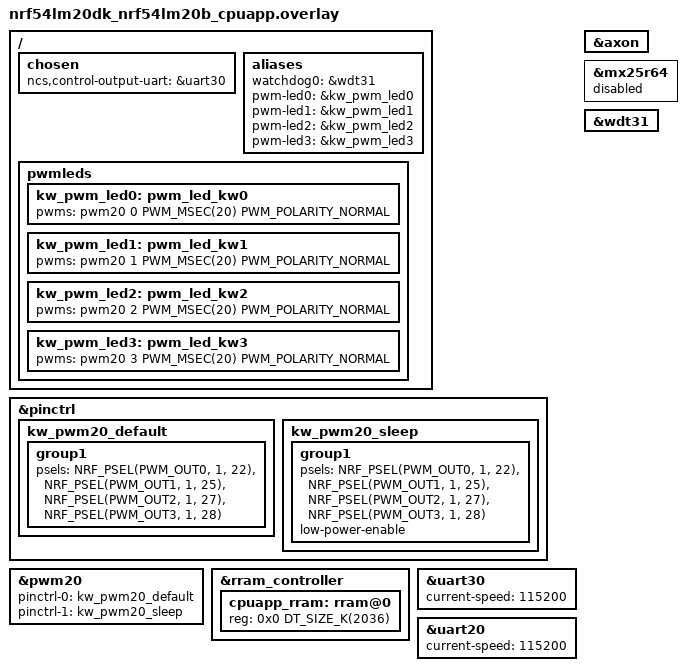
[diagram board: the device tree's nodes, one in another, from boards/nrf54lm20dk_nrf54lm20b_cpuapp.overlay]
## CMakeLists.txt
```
#
# Copyright (c) 2026 Nordic Semiconductor ASA
#
# SPDX-License-Identifier: LicenseRef-Nordic-5-Clause
#

cmake_minimum_required(VERSION 3.20.0)

find_package(Zephyr REQUIRED HINTS $ENV{ZEPHYR_BASE})
project(matter_switch)

# Enable GNU STD support.
include(${ZEPHYR_CONNECTEDHOMEIP_MODULE_DIR}/config/nrfconnect/app/enable-gnu-std.cmake)

# NORDIC SDK APP START

# Include all source files that are located in the Matter common directory.
include(${ZEPHYR_NRF_MODULE_DIR}/samples/matter/common/cmake/source_common.cmake)

# Include Data Model utils
include(${ZEPHYR_NRF_MODULE_DIR}/samples/matter/common/cmake/data_model.cmake)

include(${ZEPHYR_NRF_MODULE_DIR}/samples/matter/common/cmake/zap_helpers.cmake)
ncs_get_zap_parent_dir(ZAP_PARENT_DIR)

include(${ZEPHYR_NCS_MATTER_EDGE_AI_MODULE_DIR}/samples/common/matter_edge_ai_common.cmake)

target_include_directories(app PRIVATE
  src
  src/models/kws/nrf_edgeai_generated
  src/models/wakeword/nrf_edgeai_generated
  src/edgeAI
  ${ZAP_PARENT_DIR}
)

target_compile_options(app PRIVATE -Wno-deprecated-declarations)

target_sources(app PRIVATE
  src/main.cpp
  src/app_task.cpp
  src/nrf_edgeai_ww_kw_impl.cpp
  src/keyword_impl.c
  src/wakeword_impl.c
  src/models/wakeword/nrf_edgeai_generated/nrf_edgeai_user_model.c
  src/models/kws/nrf_edgeai_generated/nrf_edgeai_user_model.c
  src/generic_switch.cpp
)

ncs_configure_data_model()
```

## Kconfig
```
#
# Copyright (c) 2026 Nordic Semiconductor ASA
#
# SPDX-License-Identifier: LicenseRef-Nordic-5-Clause
#

# Sample configuration used for Thread networking
if OPENTHREAD

choice OPENTHREAD_NORDIC_LIBRARY_CONFIGURATION
	default OPENTHREAD_NORDIC_LIBRARY_MTD
endchoice

choice OPENTHREAD_DEVICE_TYPE
	default OPENTHREAD_MTD
endchoice

config CHIP_ENABLE_ICD_SUPPORT
	default y

# Reduce Thread TX output power to 0 dBm for SED device
config OPENTHREAD_DEFAULT_TX_POWER
	default 0

endif # OPENTHREAD

source "$(ZEPHYR_CONNECTEDHOMEIP_MODULE_DIR)/config/nrfconnect/chip-module/Kconfig.features"
source "$(ZEPHYR_CONNECTEDHOMEIP_MODULE_DIR)/config/nrfconnect/chip-module/Kconfig.defaults"
source "$(ZEPHYR_NRF_MODULE_DIR)/samples/matter/common/src/Kconfig"
source "Kconfig.zephyr"
```

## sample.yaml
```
sample:
  description: Matter Generic Switch application
  name: Matter Generic Switch

common:
  sysbuild: true
  build_only: true
  tags:
    - ci_build
    - sysbuild

tests:
  sample.matter.generic_switch.debug.dmic_adafruit:
    extra_args: 
      - EXTRA_DTC_OVERLAY_FILE=boards/dmic_adafruit.dtsi
    platform_allow:
      - nrf54lm20dk/nrf54lm20b/cpuapp
    integration_platforms:
      - nrf54lm20dk/nrf54lm20b/cpuapp
  sample.matter.generic_switch.debug.dmic_low_power:
    extra_args:
      - EXTRA_DTC_OVERLAY_FILE=boards/dmic_low_power.dtsi
    platform_allow:
      - nrf54lm20dk/nrf54lm20b/cpuapp
    integration_platforms:
      - nrf54lm20dk/nrf54lm20b/cpuapp
  sample.matter.generic_switch.debug.dmic_adafruit.release:
    extra_args:
      - EXTRA_DTC_OVERLAY_FILE=boards/dmic_adafruit.dtsi
      - FILE_SUFFIX=release
    platform_allow:
      - nrf54lm20dk/nrf54lm20b/cpuapp
    integration_platforms:
      - nrf54lm20dk/nrf54lm20b/cpuapp
  sample.matter.generic_switch.debug.dmic_low_power.release:
    extra_args:
      - EXTRA_DTC_OVERLAY_FILE=boards/dmic_low_power.dtsi
      - FILE_SUFFIX=release
    platform_allow:
      - nrf54lm20dk/nrf54lm20b/cpuapp
    integration_platforms:
      - nrf54lm20dk/nrf54lm20b/cpuapp
```

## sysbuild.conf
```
#
# Copyright (c) 2026 Nordic Semiconductor ASA
#
# SPDX-License-Identifier: LicenseRef-Nordic-5-Clause
#

SB_CONFIG_MATTER=y
SB_CONFIG_MATTER_FACTORY_DATA_GENERATE=y

SB_CONFIG_PARTITION_MANAGER=n

# Enable the DFU image compression.
SB_CONFIG_BOOTLOADER_MCUBOOT=y
SB_CONFIG_DFU_MULTI_IMAGE_PACKAGE_BUILD=y
SB_CONFIG_DFU_MULTI_IMAGE_PACKAGE_APP=y
SB_CONFIG_MCUBOOT_MODE_OVERWRITE_ONLY=y
SB_CONFIG_MCUBOOT_COMPRESSED_IMAGE_SUPPORT=y
```

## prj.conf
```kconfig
#
# Copyright (c) 2026 Nordic Semiconductor
#
# SPDX-License-Identifier: LicenseRef-Nordic-5-Clause
#

# Enable CHIP
CONFIG_CHIP=y
CONFIG_CHIP_PROJECT_CONFIG="src/chip_project_config.h"
CONFIG_CHIP_DEVICE_PRODUCT_NAME="Matter AI Switch"
CONFIG_NCS_SAMPLE_MATTER_ZAP_FILE_PATH="${APPLICATION_CONFIG_DIR}/src/generic_switch_zap/generic_switch.zap"

# 32772 == 0x8004 (example matter_switch-app)
CONFIG_CHIP_DEVICE_PRODUCT_ID=32772
CONFIG_STD_CPP17=y

# Enable Matter extended announcement and increase duration to 1 hour.
CONFIG_CHIP_BLE_EXT_ADVERTISING=y
CONFIG_CHIP_BLE_ADVERTISING_DURATION=60

# Add support for LEDs and buttons on Nordic development kits
CONFIG_DK_LIBRARY=y

# Bluetooth Low Energy configuration
CONFIG_BT_DEVICE_NAME="MatterAISwitch"

# Enable Matter pairing automatically on application start.
CONFIG_CHIP_ENABLE_PAIRING_AUTOSTART=y

# Suspend devices when the CPU goes into sleep
CONFIG_PM_DEVICE=y

# Other settings
CONFIG_THREAD_NAME=y
CONFIG_MPU_STACK_GUARD=y

CONFIG_SYSTEM_WORKQUEUE_STACK_SIZE=4096

# Memory: k_malloc pool + Matter chip heap are static (.bss) and sit before the Newlib arena
# (RAM from _end to top of SRAM). Edge AI uses malloc(); if that arena is too small, the first
# stdio/C++ lock init hits: "recursive lock allocation failed" in libc-hooks.c.
CONFIG_MAIN_STACK_SIZE=10240
CONFIG_COMMON_LIBC_MALLOC_ARENA_SIZE=-1
CONFIG_HEAP_MEM_POOL_SIZE=24576
CONFIG_CHIP_MALLOC_SYS_HEAP_SIZE=40960
CONFIG_CHIP_SYSTEM_PACKETBUFFER_POOL_SIZE=24
CONFIG_CHIP_TASK_STACK_SIZE=12288

CONFIG_MATTER_EDGEAI_TASK_THREAD_STACK_SIZE=8192
CONFIG_MATTER_EDGEAI_TASK_THREAD_PRIORITY=0

CONFIG_RESET_ON_FATAL_ERROR=n
CONFIG_CHIP_LIB_SHELL=y
CONFIG_NCS_SAMPLE_MATTER_TEST_SHELL=y

# Reduce application size
CONFIG_USE_SEGGER_RTT=n
CONFIG_MATTER_LOG_LEVEL_INF=y
CONFIG_CHIP_APP_LOG_LEVEL=3

# Enable Factory Data feature
CONFIG_CHIP_FACTORY_DATA=y
CONFIG_CHIP_FACTORY_DATA_BUILD=y

# Enable Matter Edge AI
CONFIG_FPU=y
CONFIG_MATTER_EDGEAI=y
CONFIG_MATTER_EDGEAI_DMIC=y
CONFIG_MATTER_EDGEAI_DIMMING=y

# Edge AI model configuration
CONFIG_NRF_AXON_INTERLAYER_BUFFER_SIZE=6656
CONFIG_NRF_AXON_PSUM_BUFFER_SIZE=0

# By default use Adafruit PDM module
```

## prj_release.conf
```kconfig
#
# Copyright (c) 2026 Nordic Semiconductor ASA
#
# SPDX-License-Identifier: LicenseRef-Nordic-5-Clause
#

# This sample uses Kconfig.defaults to set options common for all
# samples. This file should contain only options specific for this sample
# or overrides of default values.

# Enable CHIP
CONFIG_CHIP=y
CONFIG_CHIP_PROJECT_CONFIG="src/chip_project_config.h"
CONFIG_CHIP_DEVICE_PRODUCT_NAME="Matter AI Switch"
CONFIG_NCS_SAMPLE_MATTER_ZAP_FILE_PATH="${APPLICATION_CONFIG_DIR}/src/generic_switch_zap/generic_switch.zap"

# 32772 == 0x8004 (example matter_switch-app)
CONFIG_CHIP_DEVICE_PRODUCT_ID=32772
CONFIG_STD_CPP17=y

# Enable Matter extended announcement and increase duration to 1 hour.
CONFIG_CHIP_BLE_EXT_ADVERTISING=y
CONFIG_CHIP_BLE_ADVERTISING_DURATION=60

# Add support for LEDs and buttons on Nordic development kits
CONFIG_DK_LIBRARY=y

# Bluetooth Low Energy configuration
CONFIG_BT_DEVICE_NAME="MatterAISwitch"

# Enable Matter pairing automatically on application start.
CONFIG_CHIP_ENABLE_PAIRING_AUTOSTART=y

# Suspend devices when the CPU goes into sleep
CONFIG_PM_DEVICE=y

# Other settings
CONFIG_THREAD_NAME=y
CONFIG_MPU_STACK_GUARD=y

CONFIG_SYSTEM_WORKQUEUE_STACK_SIZE=4096

# Memory: k_malloc pool + Matter chip heap are static (.bss) and sit before the Newlib arena
# (RAM from _end to top of SRAM). Edge AI uses malloc(); if that arena is too small, the first
# stdio/C++ lock init hits: "recursive lock allocation failed" in libc-hooks.c.
CONFIG_MAIN_STACK_SIZE=10240
CONFIG_COMMON_LIBC_MALLOC_ARENA_SIZE=-1
CONFIG_HEAP_MEM_POOL_SIZE=24576
CONFIG_CHIP_MALLOC_SYS_HEAP_SIZE=40960
CONFIG_CHIP_SYSTEM_PACKETBUFFER_POOL_SIZE=24
CONFIG_CHIP_TASK_STACK_SIZE=12288

CONFIG_MATTER_EDGEAI_TASK_THREAD_STACK_SIZE=8192
CONFIG_MATTER_EDGEAI_TASK_THREAD_PRIORITY=0

CONFIG_RESET_ON_FATAL_ERROR=n
CONFIG_CHIP_LIB_SHELL=y
CONFIG_NCS_SAMPLE_MATTER_TEST_SHELL=y

# Reduce application size
CONFIG_USE_SEGGER_RTT=n
CONFIG_MATTER_LOG_LEVEL_INF=y
CONFIG_CHIP_APP_LOG_LEVEL=3

# Enable Factory Data feature
CONFIG_CHIP_FACTORY_DATA=y
CONFIG_CHIP_FACTORY_DATA_BUILD=y

# Enable Matter Edge AI
CONFIG_FPU=y
CONFIG_MATTER_EDGEAI=y
CONFIG_MATTER_EDGEAI_DMIC=y
CONFIG_MATTER_EDGEAI_DIMMING=y

# Edge AI model configuration
CONFIG_NRF_AXON_INTERLAYER_BUFFER_SIZE=6656
CONFIG_NRF_AXON_PSUM_BUFFER_SIZE=0

# Enable system reset on fatal error
CONFIG_RESET_ON_FATAL_ERROR=y

# Disable all debug features
CONFIG_USE_SEGGER_RTT=n
CONFIG_SHELL=n
CONFIG_OPENTHREAD_SHELL=n
CONFIG_CHIP_LIB_SHELL=n
CONFIG_CONSOLE=n
CONFIG_UART_CONSOLE=n
CONFIG_SERIAL=n
CONFIG_LOG=n
CONFIG_LOG_MODE_MINIMAL=n
CONFIG_ASSERT_VERBOSE=n
CONFIG_ASSERT_NO_FILE_INFO=y
CONFIG_PRINTK=n
CONFIG_PRINTK_SYNC=n
CONFIG_THREAD_NAME=n
CONFIG_BOOT_BANNER=n

# Enable LTO to decrease the flash usage.
CONFIG_LTO=y
CONFIG_ISR_TABLES_LOCAL_DECLARATION=y
```

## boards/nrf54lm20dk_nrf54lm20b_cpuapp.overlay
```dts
/*
 * Copyright (c) 2026 Nordic Semiconductor ASA
 *
 * SPDX-License-Identifier: LicenseRef-Nordic-5-Clause
 */

#include <nrf54lm20_cpuapp_internal_partitions.dtsi>

/ {
	chosen {
		ncs,control-output-uart = &uart30;
	};

	aliases {
		/* Use watchdog wdt31 as the application watchdog */
		watchdog0 = &wdt31;

		/delete-property/ pwm-led0;
		pwm-led0 = &kw_pwm_led0;
		pwm-led1 = &kw_pwm_led1;
		pwm-led2 = &kw_pwm_led2;
		pwm-led3 = &kw_pwm_led3;
	};

	pwmleds {
		kw_pwm_led0: pwm_led_kw0 {
			pwms = <&pwm20 0 PWM_MSEC(20) PWM_POLARITY_NORMAL>;
		};

		kw_pwm_led1: pwm_led_kw1 {
			pwms = <&pwm20 1 PWM_MSEC(20) PWM_POLARITY_NORMAL>;
		};

		kw_pwm_led2: pwm_led_kw2 {
			pwms = <&pwm20 2 PWM_MSEC(20) PWM_POLARITY_NORMAL>;
		};

		kw_pwm_led3: pwm_led_kw3 {
			pwms = <&pwm20 3 PWM_MSEC(20) PWM_POLARITY_NORMAL>;
		};
	};
};

&pinctrl {
	kw_pwm20_default: kw_pwm20_default {
		group1 {
			psels = <NRF_PSEL(PWM_OUT0, 1, 22)>,
				<NRF_PSEL(PWM_OUT1, 1, 25)>,
				<NRF_PSEL(PWM_OUT2, 1, 27)>,
				<NRF_PSEL(PWM_OUT3, 1, 28)>;
		};
	};

	kw_pwm20_sleep: kw_pwm20_sleep {
		group1 {
			psels = <NRF_PSEL(PWM_OUT0, 1, 22)>,
				<NRF_PSEL(PWM_OUT1, 1, 25)>,
				<NRF_PSEL(PWM_OUT2, 1, 27)>,
				<NRF_PSEL(PWM_OUT3, 1, 28)>;
			low-power-enable;
		};
	};
};

&pwm20 {
	pinctrl-0 = <&kw_pwm20_default>;
	pinctrl-1 = <&kw_pwm20_sleep>;
	pinctrl-names = "default", "sleep";
};

&rram_controller {
	cpuapp_rram: rram@0 {
		reg = <0x0 DT_SIZE_K(2036)>;
		ranges = <0x0 0x0 DT_SIZE_K(2036)>;
	};
};

&uart30 {
	status = "okay";
	current-speed = <115200>;
};

&uart20 {
	status = "okay";
	current-speed = <115200>;
};

&axon {
	status = "okay";
};

&mx25r64 {
	status = "disabled";
};

&wdt31 {
	status = "okay";
};
```

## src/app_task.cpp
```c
/*
 * Copyright (c) 2026 Nordic Semiconductor ASA
 *
 * SPDX-License-Identifier: LicenseRef-Nordic-5-Clause
 */

#include "app_task.h"

#include "app/matter_init.h"
#include "app/task_executor.h"
#include "board/board.h"
#include "clusters/identify.h"
#include "lib/core/CHIPError.h"

#include "descriptor-namespaces.h"
#include "nrf_edgeai_ww_kw_task.h"

#include <app-common/zap-generated/attributes/Accessors.h>
#include <app-common/zap-generated/cluster-objects.h>

#include <zephyr/kernel.h>
#include <zephyr/logging/log.h>

LOG_MODULE_DECLARE(app, CONFIG_CHIP_APP_LOG_LEVEL);

using namespace ::chip;
using namespace ::chip::app;
using namespace ::chip::app::Clusters;
using namespace ::chip::app::Clusters::OnOff;
using namespace ::chip::DeviceLayer;

K_SEM_DEFINE(gMatterStartedSem, 0, 1);

#define APPLICATION_BUTTON_MASK DK_BTN2_MSK

namespace
{

using SemanticTag = Globals::Structs::SemanticTagStruct::Type;

const SemanticTag gEp0TagList[] = {
	{.namespaceID = kNamespaceSwitches,
	 .tag = kTagSwitchesUp,
	 .label = chip::Optional<chip::app::DataModel::Nullable<chip::CharSpan>>(
		 {chip::app::DataModel::MakeNullable(chip::CharSpan("All", 3))})}};

const SemanticTag gEp1TagList[] = {{.namespaceID = kNamespaceSwitches,
				    .tag = kTagSwitchesUp,
				    .label = Optional<DataModel::Nullable<CharSpan>>(
					    {DataModel::MakeNullable(CharSpan("Scene 1", 8))})}};

const SemanticTag gEp2TagList[] = {{.namespaceID = kNamespaceSwitches,
				    .tag = kTagSwitchesUp,
				    .label = Optional<DataModel::Nullable<CharSpan>>(
					    {DataModel::MakeNullable(CharSpan("Scene 2", 8))})}};

const SemanticTag gEp3TagList[] = {{.namespaceID = kNamespaceSwitches,
				    .tag = kTagSwitchesUp,
				    .label = Optional<DataModel::Nullable<CharSpan>>(
					    {DataModel::MakeNullable(CharSpan("Scene 3", 8))})}};

const SemanticTag gEp4TagList[] = {{.namespaceID = kNamespaceSwitches,
				    .tag = kTagSwitchesUp,
				    .label = Optional<DataModel::Nullable<CharSpan>>(
					    {DataModel::MakeNullable(CharSpan("Scene 4", 8))})}};

Nrf::Matter::IdentifyCluster sIdentifyCluster(AppTask::Instance().GetSwitchAll().GetEndpointId());
Nrf::Matter::IdentifyCluster
	sIdentifyClusterScene1(AppTask::Instance().GetSwitchScene1().GetEndpointId());
Nrf::Matter::IdentifyCluster
	sIdentifyClusterScene2(AppTask::Instance().GetSwitchScene2().GetEndpointId());
Nrf::Matter::IdentifyCluster
	sIdentifyClusterScene3(AppTask::Instance().GetSwitchScene3().GetEndpointId());
Nrf::Matter::IdentifyCluster
	sIdentifyClusterScene4(AppTask::Instance().GetSwitchScene4().GetEndpointId());

void ButtonEventHandler(Nrf::ButtonState state, Nrf::ButtonMask hasChanged)
{
	if ((APPLICATION_BUTTON_MASK & state & hasChanged)) {
		auto position = AppTask::Instance().GetSwitchAll().GetPosition();
		position = (position == Nrf::Matter::GenericSwitch::Position::On)
				   ? Nrf::Matter::GenericSwitch::Position::Off
				   : Nrf::Matter::GenericSwitch::Position::On;

		if (position == Nrf::Matter::GenericSwitch::Position::On) {
			(void)AppTask::Instance().GetSwitchAll().ShortPress();
		} else {
			(void)AppTask::Instance().GetSwitchAll().LongPress();
		}
	}
}

void MatterAppEventHandler(const chip::DeviceLayer::ChipDeviceEvent *event, intptr_t arg)
{
	ARG_UNUSED(arg);

	switch (event->Type) {
	case chip::DeviceLayer::DeviceEventType::kServerReady:
		EdgeAITask::Instance().Enable();
		k_sem_give(&gMatterStartedSem);
		break;
	case chip::DeviceLayer::DeviceEventType::kCHIPoBLEConnectionEstablished:
		EdgeAITask::Instance().Disable();
		break;
	default:
		break;
	}
}

} // namespace

AppTask::AppTask()
	: mGenericSwitch_All(1, gEp0TagList, 1), mGenericSwitch_Scene1(2, gEp1TagList, 1),
	  mGenericSwitch_Scene2(3, gEp2TagList, 1), mGenericSwitch_Scene3(4, gEp3TagList, 1),
	  mGenericSwitch_Scene4(5, gEp4TagList, 1)
{
}

CHIP_ERROR AppTask::InitSwitches()
{
	ReturnErrorOnFailure(mGenericSwitch_All.Init());
	ReturnErrorOnFailure(mGenericSwitch_Scene1.Init());
	ReturnErrorOnFailure(mGenericSwitch_Scene2.Init());
	ReturnErrorOnFailure(mGenericSwitch_Scene3.Init());
	ReturnErrorOnFailure(mGenericSwitch_Scene4.Init());

	return CHIP_NO_ERROR;
}

CHIP_ERROR AppTask::Init()
{
	ReturnErrorOnFailure(
		Nrf::Matter::PrepareServer(Nrf::Matter::InitData{.mPostServerInitClbk = [] {
			ReturnErrorOnFailure(AppTask::Instance().InitSwitches());
			return CHIP_NO_ERROR;
		}}));

	if (!Nrf::GetBoard().Init(ButtonEventHandler)) {
		LOG_ERR("User interface initialization failed.");
		return CHIP_ERROR_INCORRECT_STATE;
	}

	ReturnErrorOnFailure(Nrf::Matter::RegisterEventHandler(MatterAppEventHandler, 0));
	ReturnErrorOnFailure(
		Nrf::Matter::RegisterEventHandler(Nrf::Board::DefaultMatterEventHandler, 0));

	ReturnErrorOnFailure(sIdentifyCluster.Init());
	ReturnErrorOnFailure(sIdentifyClusterScene1.Init());
	ReturnErrorOnFailure(sIdentifyClusterScene2.Init());
	ReturnErrorOnFailure(sIdentifyClusterScene3.Init());
	ReturnErrorOnFailure(sIdentifyClusterScene4.Init());

	return Nrf::Matter::StartServer();
}

CHIP_ERROR AppTask::StartApp()
{
	ReturnErrorOnFailure(Init());

	if (!EdgeAITask::Instance().Start()) {
		return CHIP_ERROR_INTERNAL;
	}

	while (true) {
		Nrf::DispatchNextTask();
	}

	return CHIP_NO_ERROR;
}

void MatterPostAttributeChangeCallback(const chip::app::ConcreteAttributePath &attributePath,
				       uint8_t type, uint16_t size, uint8_t *value)
{
	ClusterId pathClusterId = attributePath.mClusterId;
	AttributeId pathAttributeId = attributePath.mAttributeId;

	if (pathClusterId == OnOff::Id && pathAttributeId == OnOff::Attributes::OnOff::Id) {
		if (!value) {
			LOG_ERR("Invalid value for OnOff attribute");
			return;
		}

		const bool valueInvert = !*value;

		LOG_INF("Cluster OnOff: attribute OnOff set to %" PRIu8 "", valueInvert);

		Nrf::GetBoard().GetLED(Nrf::DeviceLeds::LED2).Set(valueInvert);
	}
}
```

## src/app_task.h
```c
/*
 * Copyright (c) 2026 Nordic Semiconductor ASA
 *
 * SPDX-License-Identifier: LicenseRef-Nordic-5-Clause
 */

#pragma once

#include "generic_switch.h"

#include <lib/core/CHIPError.h>

class AppTask
{
public:
	static AppTask &Instance()
	{
		static AppTask sAppTask;
		return sAppTask;
	}

	CHIP_ERROR StartApp();

	Nrf::Matter::GenericSwitch &GetSwitchAll()
	{
		return mGenericSwitch_All;
	}
	Nrf::Matter::GenericSwitch &GetSwitchScene1()
	{
		return mGenericSwitch_Scene1;
	}
	Nrf::Matter::GenericSwitch &GetSwitchScene2()
	{
		return mGenericSwitch_Scene2;
	}
	Nrf::Matter::GenericSwitch &GetSwitchScene3()
	{
		return mGenericSwitch_Scene3;
	}
	Nrf::Matter::GenericSwitch &GetSwitchScene4()
	{
		return mGenericSwitch_Scene4;
	}

private:
	AppTask();

	CHIP_ERROR Init();
	CHIP_ERROR InitSwitches();

	Nrf::Matter::GenericSwitch mGenericSwitch_All;
	Nrf::Matter::GenericSwitch mGenericSwitch_Scene1;
	Nrf::Matter::GenericSwitch mGenericSwitch_Scene2;
	Nrf::Matter::GenericSwitch mGenericSwitch_Scene3;
	Nrf::Matter::GenericSwitch mGenericSwitch_Scene4;
};
```

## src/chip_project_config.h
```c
/*
 * Copyright (c) 2026 Nordic Semiconductor ASA
 *
 * SPDX-License-Identifier: LicenseRef-Nordic-5-Clause
 */

/**
 *    @file
 *          Example project configuration file for CHIP.
 *
 *          This is a place to put application or project-specific overrides
 *          to the default configuration values for general CHIP features.
 *
 */

#pragma once

/* Empty file */
```

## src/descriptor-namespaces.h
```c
/*
 * Copyright (c) 2026 Nordic Semiconductor ASA
 *
 * SPDX-License-Identifier: LicenseRef-Nordic-5-Clause
 */

#pragma once

// Please refer to
// https://github.com/CHIP-Specifications/connectedhomeip-spec/blob/master/src/namespaces
constexpr const uint8_t kNamespaceSwitches = 0x43;

// Switches namespace: 0x43, tag = 0x03 (Up)
constexpr const uint8_t kTagSwitchesUp = 0x03;
```

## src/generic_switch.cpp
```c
/*
 * Copyright (c) 2026 Nordic Semiconductor ASA
 *
 * SPDX-License-Identifier: LicenseRef-Nordic-5-Clause
 */

#include "generic_switch.h"

#include <app-common/zap-generated/attributes/Accessors.h>
#include <app/clusters/switch-server/switch-server.h>
#include <app/util/attribute-storage.h>
#include <lib/support/TypeTraits.h>

#include <zephyr/logging/log.h>

using namespace chip;
using namespace chip::app;
using namespace chip::app::Clusters;
using namespace chip::app::Clusters::Switch;
using chip::Protocols::InteractionModel::Status;

LOG_MODULE_DECLARE(app, CONFIG_CHIP_APP_LOG_LEVEL);

namespace
{

CHIP_ERROR VerifyFeatureEnabled(bool enabled)
{
	return enabled ? CHIP_NO_ERROR : CHIP_ERROR_UNSUPPORTED_CHIP_FEATURE;
}

} // namespace

namespace Nrf
{
namespace Matter
{

bool GenericSwitch::HasFeature(Feature feature) const
{
	uint32_t featureMap = 0;

	if (Attributes::FeatureMap::Get(mEndpointId, &featureMap) != Status::Success) {
		return false;
	}

	return (featureMap & to_underlying(feature)) != 0;
}

CHIP_ERROR GenericSwitch::Init()
{
	if ((mTagList != nullptr) && (mTagListSize > 0)) {
		ReturnErrorOnFailure(
			SetTagList(mEndpointId, Span<const SemanticTag>(mTagList, mTagListSize)));
	}

	return CHIP_NO_ERROR;
}

CHIP_ERROR GenericSwitch::Latch()
{
	ReturnErrorOnFailure(VerifyFeatureEnabled(HasFeature(Feature::kLatchingSwitch)));

	mLatchState = !mLatchState;

	const uint8_t position = mLatchState ? 1 : 0;

	SwitchServer::Instance().OnSwitchLatch(mEndpointId, position);
	LOG_INF("Latch endpoint %u position %u", mEndpointId, position);

	return CHIP_NO_ERROR;
}

CHIP_ERROR GenericSwitch::ShortPress()
{
	mPosition = Position::On;
	ReturnErrorOnFailure(VerifyFeatureEnabled(HasFeature(Feature::kMomentarySwitch)));

	SwitchServer::Instance().OnInitialPress(mEndpointId, static_cast<uint8_t>(mPosition));
	SwitchServer::Instance().OnShortRelease(mEndpointId, static_cast<uint8_t>(mPosition));
	LOG_INF("ShortPress endpoint %u position %u", mEndpointId, static_cast<uint8_t>(mPosition));

	return CHIP_NO_ERROR;
}

CHIP_ERROR GenericSwitch::LongPress()
{
	mPosition = Position::Off;
	ReturnErrorOnFailure(VerifyFeatureEnabled(HasFeature(Feature::kMomentarySwitchLongPress)));

	SwitchServer::Instance().OnLongPress(mEndpointId, static_cast<uint8_t>(mPosition));
	SwitchServer::Instance().OnLongRelease(mEndpointId, static_cast<uint8_t>(mPosition));
	LOG_INF("LongRelease endpoint %u position %u", mEndpointId,
		static_cast<uint8_t>(mPosition));

	return CHIP_NO_ERROR;
}

CHIP_ERROR GenericSwitch::MultiplePress(uint8_t count)
{
	ReturnErrorOnFailure(VerifyFeatureEnabled(HasFeature(Feature::kMomentarySwitchRelease)));

	SwitchServer::Instance().OnInitialPress(mEndpointId, static_cast<uint8_t>(mPosition));
	SwitchServer::Instance().OnMultiPressOngoing(mEndpointId, static_cast<uint8_t>(mPosition),
						     count);
	LOG_INF("MultiplePress endpoint %u position %u count %u", mEndpointId,
		static_cast<uint8_t>(mPosition), count);

	return CHIP_NO_ERROR;
}
} // namespace Matter
} // namespace Nrf
```

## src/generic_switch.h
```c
/*
 * Copyright (c) 2026 Nordic Semiconductor ASA
 *
 * SPDX-License-Identifier: LicenseRef-Nordic-5-Clause
 */

#pragma once

#include <app-common/zap-generated/cluster-objects.h>
#include <lib/core/CHIPError.h>
#include <lib/core/DataModelTypes.h>

namespace Nrf
{
namespace Matter
{

class GenericSwitch
{
public:
	using SemanticTag = chip::app::Clusters::Globals::Structs::SemanticTagStruct::Type;

	enum class Position : uint8_t {
		On = 0,
		Off = 1,
	};

	GenericSwitch(chip::EndpointId endpointId, const SemanticTag *tagList = nullptr,
		      size_t tagListSize = 0)
		: mEndpointId(endpointId), mTagList(tagList), mTagListSize(tagListSize)
	{
	}

	CHIP_ERROR Init();
	CHIP_ERROR Latch();
	CHIP_ERROR ShortPress();
	CHIP_ERROR LongPress();
	CHIP_ERROR MultiplePress(uint8_t count);

	Position GetPosition() const
	{
		return mPosition;
	}
	chip::EndpointId GetEndpointId() const
	{
		return mEndpointId;
	}

private:
	bool HasFeature(chip::app::Clusters::Switch::Feature feature) const;

	chip::EndpointId mEndpointId;
	const SemanticTag *mTagList;
	size_t mTagListSize;
	bool mLatchState = false;
	Position mPosition = Position::Off;
};

} // namespace Matter
} // namespace Nrf
```

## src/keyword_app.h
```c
/*
 * Copyright (c) 2026 Nordic Semiconductor ASA
 *
 * SPDX-License-Identifier: LicenseRef-Nordic-5-Clause
 */

/**
 * @file keyword_app.h
 * @brief Application-specific keyword class indices for the generic_switch sample.
 *
 * Indices must match the KWS model output classes.
 */

#pragma once

#include <stddef.h>
#include <stdint.h>

typedef enum keyword_labels_e {
	KEYWORD_LIGHT = 0,
	KEYWORD_OFF = 1,
	KEYWORD_ON = 2,
	KEYWORD_OTHER = 3,
	KEYWORD_SCENE_FOUR = 4,
	KEYWORD_SCENE_ONE = 5,
	KEYWORD_SCENE_THREE = 6,
	KEYWORD_SCENE_TWO = 7,
	KEYWORD_SILENCE = 8,
	KEYWORD_TOGGLE_LIGHT = 9,

	KEYWORDS_cnt
} keyword_labels_t;
```

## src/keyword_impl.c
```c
/*
 * Copyright (c) 2026 Nordic Semiconductor ASA
 *
 * SPDX-License-Identifier: LicenseRef-Nordic-5-Clause
 */

#include "keyword.h"
#include "keyword_app.h"

#include "models/kws/nrf_edgeai_generated/nrf_edgeai_user_model.h"

static const keyword_class_cfg_t sKeywordClassesCfg[] = {
	[KEYWORD_OTHER] = {.name = "OTHER", .countNeeded = 4, .thresholdPercent = 0},
	[KEYWORD_SCENE_FOUR] = {.name = "SCENE_FOUR", .countNeeded = 2, .thresholdPercent = 0},
	[KEYWORD_SCENE_ONE] = {.name = "SCENE_ONE", .countNeeded = 2, .thresholdPercent = 0},
	[KEYWORD_SCENE_THREE] = {.name = "SCENE_THREE", .countNeeded = 2, .thresholdPercent = 0},
	[KEYWORD_SCENE_TWO] = {.name = "SCENE_TWO", .countNeeded = 2, .thresholdPercent = 0},
	[KEYWORD_SILENCE] = {.name = "SILENCE", .countNeeded = 4, .thresholdPercent = 0},
	[KEYWORD_TOGGLE_LIGHT] = {.name = "TOGGLE_LIGHT",
				  .countNeeded = 2,
				  .thresholdPercent = 0},
};

nrf_edgeai_t *KeywordAppModelGet(void)
{
	return nrf_edgeai_user_model_kws();
}

const keyword_class_cfg_t *KeywordAppGetClassesCfg(void)
{
	return sKeywordClassesCfg;
}

size_t KeywordAppGetClassesCount(void)
{
	return KEYWORDS_cnt;
}

uint16_t KeywordAppGetOtherClass(void)
{
	return KEYWORD_OTHER;
}

uint16_t KeywordAppGetSilenceClass(void)
{
	return KEYWORD_SILENCE;
}

bool KeywordAppIsCommandComponent(uint16_t predictedClass)
{
	return (predictedClass < KEYWORDS_cnt) && (predictedClass != KEYWORD_OTHER) &&
	       (predictedClass != KEYWORD_SILENCE);
}

bool KeywordAppIsActionable(uint16_t predictedClass)
{
	return (predictedClass == KEYWORD_SCENE_FOUR) || (predictedClass == KEYWORD_SCENE_ONE) ||
	       (predictedClass == KEYWORD_SCENE_THREE) || (predictedClass == KEYWORD_SCENE_TWO) ||
	       (predictedClass == KEYWORD_TOGGLE_LIGHT);
}
```

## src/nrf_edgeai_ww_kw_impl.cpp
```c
/*
 * Copyright (c) 2026 Nordic Semiconductor ASA
 *
 * SPDX-License-Identifier: LicenseRef-Nordic-5-Clause
 */

#include "nrf_edgeai_ww_kw_task.h"

#include "app_task.h"
#include "dimming_effect.h"
#include "keyword_app.h"
#include "platform/CHIPDeviceLayer.h"
#include "platform/PlatformManager.h"

#include <zephyr/logging/log.h>

LOG_MODULE_DECLARE(edgeai_ww_kw, CONFIG_MATTER_EDGEAI_WW_KW_LOG_LEVEL);

using namespace chip::DeviceLayer;

/**
 * Currently, commercial ecosystems support the Generic Switch only in momentary mode.
 * The switch recognizes three actions: Short Press, Long Press, and Multiple Press.
 * However, within the ecosystem app, only a single steering device state can be assigned to each
 * action. To enable toggling the device state, we map Short Press and Long Press to "on" and "off"
 * actions, respectively. As a result, the "Toggle" keyword can be handled by alternately triggering
 * either a Short Press or a Long Press.
 */

void EdgeAIWwKwHandleKeyword(uint16_t keywordClass)
{
	switch (keywordClass) {
	case KEYWORD_TOGGLE_LIGHT:
		SystemLayer().ScheduleLambda([] {
			LOG_DBG("Detected Toggle keyword");
			auto position = AppTask::Instance().GetSwitchAll().GetPosition();
			position = (position == Nrf::Matter::GenericSwitch::Position::On)
					   ? Nrf::Matter::GenericSwitch::Position::Off
					   : Nrf::Matter::GenericSwitch::Position::On;
			if (position == Nrf::Matter::GenericSwitch::Position::On) {
				(void)AppTask::Instance().GetSwitchAll().ShortPress();
			} else {
				(void)AppTask::Instance().GetSwitchAll().LongPress();
			}
		});
		break;
	case KEYWORD_SCENE_ONE:
		SystemLayer().ScheduleLambda([] {
			LOG_DBG("Detected Scene 1");
			(void)AppTask::Instance().GetSwitchScene1().ShortPress();
		});
		break;
	case KEYWORD_SCENE_TWO:
		SystemLayer().ScheduleLambda([] {
			LOG_DBG("Detected Scene 2");
			(void)AppTask::Instance().GetSwitchScene2().ShortPress();
		});
		break;
	case KEYWORD_SCENE_THREE:
		SystemLayer().ScheduleLambda([] {
			LOG_DBG("Detected Scene 3");
			(void)AppTask::Instance().GetSwitchScene3().ShortPress();
		});
		break;
	case KEYWORD_SCENE_FOUR:
		SystemLayer().ScheduleLambda([] {
			LOG_DBG("Detected Scene 4");
			(void)AppTask::Instance().GetSwitchScene4().ShortPress();
		});
		break;
	default:
		LOG_DBG("Not a valid keyword (class %u)", keywordClass);
		break;
	}
}

void EdgeAIWwKwOnWakewordDetected(void)
{
	if (Nrf::DimmingEffect::IsAvailable()) {
		Nrf::DimmingEffect::RequestStartViaTimer();
	}
}

void EdgeAIWwKwOnKeywordSessionEnd(void)
{
	Nrf::DimmingEffect::Stop();
}

bool EdgeAIWwKwAppInit(void)
{
	if (Nrf::DimmingEffect::IsAvailable()) {
		Nrf::DimmingEffect::Config dimCfg;

		dimCfg.effectTimeoutS = CONFIG_MATTER_EDGEAI_KEYWORD_DETECTION_TIMEOUT_S;
		dimCfg.blinkPairsMultiplier = 3;
		if (Nrf::DimmingEffect::Init(dimCfg) != 0) {
			return false;
		}
	}

	return true;
}
```

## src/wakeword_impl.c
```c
/*
 * Copyright (c) 2026 Nordic Semiconductor ASA
 *
 * SPDX-License-Identifier: LicenseRef-Nordic-5-Clause
 */

#include "wakeword.h"

#include "models/wakeword/nrf_edgeai_generated/nrf_edgeai_user_model.h"

nrf_edgeai_t *WakewordAppModelGet(void)
{
	return nrf_edgeai_user_model_ww();
}
```
